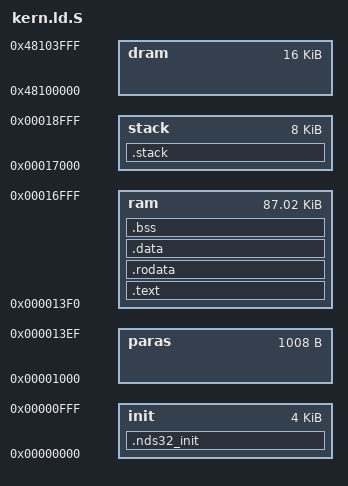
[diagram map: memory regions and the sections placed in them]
/* This file is generated by nds_ldsag (version (2015-08-19) ). */
MEMORY
{
	init    : ORIGIN = 0x00000000, LENGTH = 0x00001000
	/* 96k ram area for arisc code */
	paras   : ORIGIN = 0x00001000, LENGTH = 0x000003f0
	ram     : ORIGIN = 0x000013f0, LENGTH = 0x00015c10
	stack	: ORIGIN = 0x00017000, LENGTH = 0x00002000
	/* 16k dram area, 12K for code, 4K for back data */
	dram    : ORIGIN = 0x48100000, LENGTH = 0x00004000
}


ENTRY(_start)
SECTIONS
{
	PROVIDE (__executable_start = 0x00000000);
	.nds32_init :
		{
			*(.nds32_init )
		} > init

	__text_start = .;
	PROVIDE (__text_start = .);
	.text 	:
		{
			*(.text .stub .text.*)
			. = ALIGN(4);
		} > ram
	PROVIDE (__text_end = .);

	__rodata_start = .;
	PROVIDE (__rodata_start = .);
	.rodata ALIGN(4): AT(__rodata_start)
		{
			*(.rodata .rodata.*)
		} > ram
	PROVIDE (__rodata_end = .);

	__data_start = .;
	PROVIDE (__data_start = .);
	.data ALIGN(4):AT(__data_start)
		{
			*(.data .data.*)
			. = ALIGN(4);
		} > ram
	PROVIDE (__data_end = .);

	__bss_start = .;
	PROVIDE (__bss_start = .);
	.bss ALIGN(4): AT(__bss_start)
		{
			*(.dynbss )
			*(.bss .bss.*)
			*(COMMON )
			. = ALIGN(4);
		} > ram
	PROVIDE (__bss_end = .);

	. = ALIGN(4);
	.stack :
		{
			stack_limit_addr = ALIGN(0x4);
			*(.stack)
			stack_base_addr = ALIGN(0x4);
		} > stack
	_end = .;
	PROVIDE (end = .);
}
